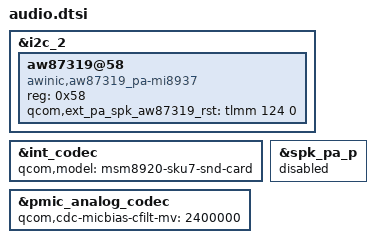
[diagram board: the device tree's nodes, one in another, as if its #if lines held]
&i2c_2  {
	aw87319@58{ /*AW87319 PA*/
#ifdef CONFIG_SND_SOC_AW87319_MI8937
		compatible = "awinic,aw87319_pa-mi8937";
#else
		compatible = "awinic,aw87319_pa";
#endif
		reg = <0x58>;
		qcom,ext_pa_spk_aw87319_rst = <&tlmm 124 0>;
	};
};

&int_codec {
	qcom,model = "msm8920-sku7-snd-card";
};

&pmic_analog_codec {
	qcom,cdc-micbias-cfilt-mv = <2400000>;
};

#ifdef MI8937_V2
&spk_pa_p {
	status = "disabled";
};
#endif
